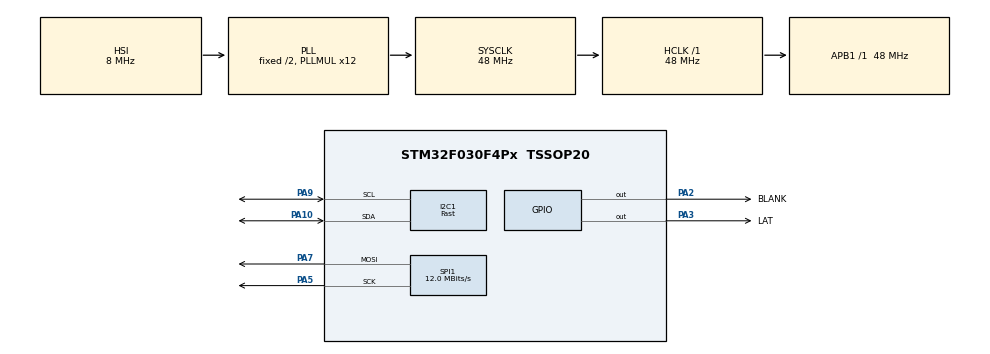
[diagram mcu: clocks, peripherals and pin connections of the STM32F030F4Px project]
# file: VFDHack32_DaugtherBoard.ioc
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Dma.I2C1_TX.0.Direction=DMA_MEMORY_TO_PERIPH
Dma.I2C1_TX.0.Instance=DMA1_Channel2
Dma.I2C1_TX.0.MemDataAlignment=DMA_MDATAALIGN_BYTE
Dma.I2C1_TX.0.MemInc=DMA_MINC_ENABLE
Dma.I2C1_TX.0.Mode=DMA_NORMAL
Dma.I2C1_TX.0.PeriphDataAlignment=DMA_PDATAALIGN_BYTE
Dma.I2C1_TX.0.PeriphInc=DMA_PINC_DISABLE
Dma.I2C1_TX.0.Priority=DMA_PRIORITY_MEDIUM
Dma.Request0=I2C1_TX
Dma.Request1=SPI1_TX
Dma.SPI1_TX.1.Direction=DMA_MEMORY_TO_PERIPH
Dma.SPI1_TX.1.Instance=DMA1_Channel3
Dma.SPI1_TX.1.MemDataAlignment=DMA_MDATAALIGN_BYTE
Dma.SPI1_TX.1.MemInc=DMA_MINC_ENABLE
Dma.SPI1_TX.1.Mode=DMA_NORMAL
Dma.SPI1_TX.1.PeriphDataAlignment=DMA_PDATAALIGN_BYTE
Dma.SPI1_TX.1.PeriphInc=DMA_PINC_DISABLE
Dma.SPI1_TX.1.Priority=DMA_PRIORITY_HIGH
I2C1.GeneralCallMode=I2C_GENERALCALL_DISABLE
I2C1.I2C_Speed_Mode=I2C_Fast
I2C1.OwnAddress=0x17
I2C1.Timing=0x0000020B
Mcu.Family=STM32F0
Mcu.Name=STM32F030F4Px
Mcu.Package=TSSOP20
NVIC.DMA1_Channel2_3_IRQn=true\:0\:0\:false\:false\:true\:false\:true
NVIC.I2C1_IRQn=true\:0\:0\:false\:false\:true\:true\:true
PA10.Mode=I2C
PA10.Signal=I2C1_SDA
PA13.Mode=Serial_Wire
PA13.Signal=SYS_SWDIO
PA14.Mode=Serial_Wire
PA14.Signal=SYS_SWCLK
PA2.GPIO_Label=BLANK
PA2.GPIO_Speed=GPIO_SPEED_FREQ_HIGH
PA2.Signal=GPIO_Output
PA3.GPIO_Label=LAT
PA3.GPIO_Speed=GPIO_SPEED_FREQ_HIGH
PA3.Signal=GPIO_Output
PA5.Mode=TX_Only_Simplex_Unidirect_Master
PA5.Signal=SPI1_SCK
PA7.Mode=TX_Only_Simplex_Unidirect_Master
PA7.Signal=SPI1_MOSI
PA9.Mode=I2C
PA9.Signal=I2C1_SCL
ProjectManager.HeapSize=0x200
ProjectManager.StackSize=0x400
ProjectManager.TargetToolchain=STM32CubeIDE
RCC.AHBFreq_Value=48000000
RCC.APB1Freq_Value=48000000
RCC.APB1TimFreq_Value=48000000
RCC.HCLKFreq_Value=48000000
RCC.PLLMUL=RCC_PLL_MUL12
RCC.SYSCLKFreq_VALUE=48000000
RCC.SYSCLKSource=RCC_SYSCLKSOURCE_PLLCLK
SPI1.BaudRatePrescaler=SPI_BAUDRATEPRESCALER_4
SPI1.CLKPolarity=SPI_POLARITY_HIGH
SPI1.CalculateBaudRate=12.0 MBits/s
SPI1.DataSize=SPI_DATASIZE_8BIT
SPI1.Direction=SPI_DIRECTION_2LINES
SPI1.FirstBit=SPI_FIRSTBIT_LSB
SPI1.Mode=SPI_MODE_MASTER
SPI1.VirtualType=VM_MASTER
board=custom

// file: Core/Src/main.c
/* USER CODE BEGIN Header */
/**
  ******************************************************************************
  * @file           : main.c
  * @brief          : Main program body
  ******************************************************************************
  * @attention
  *
  * <h2><center>&copy; Copyright (c) 2021 STMicroelectronics.
  * All rights reserved.</center></h2>
  *
  * This software component is licensed by ST under BSD 3-Clause license,
  * the "License"; You may not use this file except in compliance with the
  * License. You may obtain a copy of the License at:
  *                        opensource.org/licenses/BSD-3-Clause
  *
  ******************************************************************************
  */
/* USER CODE END Header */
#include "main.h"

/* USER CODE BEGIN Includes */
#include "MN15439A.h"
#include <stdint.h>
#include <string.h>

/* USER CODE END Includes */

/* USER CODE BEGIN PTD */
MN15439A VFDDisp;
/* USER CODE END PTD */

I2C_HandleTypeDef hi2c1;
DMA_HandleTypeDef hdma_i2c1_tx;

SPI_HandleTypeDef hspi1;
DMA_HandleTypeDef hdma_spi1_tx;

/* USER CODE BEGIN PV */
// Grid number counter
uint8_t GridNum = 1;
/* USER CODE END PV */

void SystemClock_Config(void);
static void MX_GPIO_Init(void);
static void MX_DMA_Init(void);
static void MX_SPI1_Init(void);
static void MX_I2C1_Init(void);

int main(void)
{

  /* MCU Configuration--------------------------------------------------------*/

  /* Reset of all peripherals, Initializes the Flash interface and the Systick. */
  HAL_Init();

  /* Configure the system clock */
  SystemClock_Config();

  /* Initialize all configured peripherals */
  MX_GPIO_Init();
  MX_DMA_Init();
  MX_SPI1_Init();
  MX_I2C1_Init();
  /* USER CODE BEGIN 2 */

  // VFD init
  VFDsetup(&VFDDisp, &hspi1, GPIOA, BLANK_Pin, LAT_Pin);

  /* USER CODE END 2 */

  /* Infinite loop */
  while (1)
  {

    /* USER CODE BEGIN 3 */
		VFDLoadBMP(&VFDDisp, GridNum++);
		  if(GridNum > 52)
			  GridNum = 1;
  }
  /* USER CODE END 3 */
}

void SystemClock_Config(void)
{
  RCC_OscInitTypeDef RCC_OscInitStruct = {0};
  RCC_ClkInitTypeDef RCC_ClkInitStruct = {0};
  RCC_PeriphCLKInitTypeDef PeriphClkInit = {0};

  /** Initializes the RCC Oscillators according to the specified parameters
  * in the RCC_OscInitTypeDef structure.
  */
  RCC_OscInitStruct.OscillatorType = RCC_OSCILLATORTYPE_HSI;
  RCC_OscInitStruct.HSIState = RCC_HSI_ON;
  RCC_OscInitStruct.HSICalibrationValue = RCC_HSICALIBRATION_DEFAULT;
  RCC_OscInitStruct.PLL.PLLState = RCC_PLL_ON;
  RCC_OscInitStruct.PLL.PLLSource = RCC_PLLSOURCE_HSI;
  RCC_OscInitStruct.PLL.PLLMUL = RCC_PLL_MUL12;
  RCC_OscInitStruct.PLL.PREDIV = RCC_PREDIV_DIV1;
  if (HAL_RCC_OscConfig(&RCC_OscInitStruct) != HAL_OK)
  {
    Error_Handler();
  }
  /** Initializes the CPU, AHB and APB buses clocks
  */
  RCC_ClkInitStruct.ClockType = RCC_CLOCKTYPE_HCLK|RCC_CLOCKTYPE_SYSCLK
                              |RCC_CLOCKTYPE_PCLK1;
  RCC_ClkInitStruct.SYSCLKSource = RCC_SYSCLKSOURCE_PLLCLK;
  RCC_ClkInitStruct.AHBCLKDivider = RCC_SYSCLK_DIV1;
  RCC_ClkInitStruct.APB1CLKDivider = RCC_HCLK_DIV1;

  if (HAL_RCC_ClockConfig(&RCC_ClkInitStruct, FLASH_LATENCY_1) != HAL_OK)
  {
    Error_Handler();
  }
  PeriphClkInit.PeriphClockSelection = RCC_PERIPHCLK_I2C1;
  PeriphClkInit.I2c1ClockSelection = RCC_I2C1CLKSOURCE_HSI;
  if (HAL_RCCEx_PeriphCLKConfig(&PeriphClkInit) != HAL_OK)
  {
    Error_Handler();
  }
}

static void MX_I2C1_Init(void)
{

  hi2c1.Instance = I2C1;
  hi2c1.Init.Timing = 0x0000020B;
  hi2c1.Init.OwnAddress1 = 46;
  hi2c1.Init.AddressingMode = I2C_ADDRESSINGMODE_7BIT;
  hi2c1.Init.DualAddressMode = I2C_DUALADDRESS_DISABLE;
  hi2c1.Init.OwnAddress2 = 0;
  hi2c1.Init.OwnAddress2Masks = I2C_OA2_NOMASK;
  hi2c1.Init.GeneralCallMode = I2C_GENERALCALL_DISABLE;
  hi2c1.Init.NoStretchMode = I2C_NOSTRETCH_DISABLE;
  if (HAL_I2C_Init(&hi2c1) != HAL_OK)
  {
    Error_Handler();
  }
  /** Configure Analogue filter
  */
  if (HAL_I2CEx_ConfigAnalogFilter(&hi2c1, I2C_ANALOGFILTER_ENABLE) != HAL_OK)
  {
    Error_Handler();
  }
  /** Configure Digital filter
  */
  if (HAL_I2CEx_ConfigDigitalFilter(&hi2c1, 0) != HAL_OK)
  {
    Error_Handler();
  }

}

static void MX_SPI1_Init(void)
{

  /* SPI1 parameter configuration*/
  hspi1.Instance = SPI1;
  hspi1.Init.Mode = SPI_MODE_MASTER;
  hspi1.Init.Direction = SPI_DIRECTION_2LINES;
  hspi1.Init.DataSize = SPI_DATASIZE_8BIT;
  hspi1.Init.CLKPolarity = SPI_POLARITY_HIGH;
  hspi1.Init.CLKPhase = SPI_PHASE_1EDGE;
  hspi1.Init.NSS = SPI_NSS_SOFT;
  hspi1.Init.BaudRatePrescaler = SPI_BAUDRATEPRESCALER_4;
  hspi1.Init.FirstBit = SPI_FIRSTBIT_LSB;
  hspi1.Init.TIMode = SPI_TIMODE_DISABLE;
  hspi1.Init.CRCCalculation = SPI_CRCCALCULATION_DISABLE;
  hspi1.Init.CRCPolynomial = 7;
  hspi1.Init.CRCLength = SPI_CRC_LENGTH_DATASIZE;
  hspi1.Init.NSSPMode = SPI_NSS_PULSE_ENABLE;
  if (HAL_SPI_Init(&hspi1) != HAL_OK)
  {
    Error_Handler();
  }

}

static void MX_DMA_Init(void)
{

  /* DMA controller clock enable */
  __HAL_RCC_DMA1_CLK_ENABLE();

  /* DMA interrupt init */
  /* DMA1_Channel2_3_IRQn interrupt configuration */
  HAL_NVIC_SetPriority(DMA1_Channel2_3_IRQn, 0, 0);
  HAL_NVIC_EnableIRQ(DMA1_Channel2_3_IRQn);

}

static void MX_GPIO_Init(void)
{
  GPIO_InitTypeDef GPIO_InitStruct = {0};

  /* GPIO Ports Clock Enable */
  __HAL_RCC_GPIOA_CLK_ENABLE();

  /*Configure GPIO pin Output Level */
  HAL_GPIO_WritePin(GPIOA, BLANK_Pin|LAT_Pin, GPIO_PIN_RESET);

  /*Configure GPIO pins : BLANK_Pin LAT_Pin */
  GPIO_InitStruct.Pin = BLANK_Pin|LAT_Pin;
  GPIO_InitStruct.Mode = GPIO_MODE_OUTPUT_PP;
  GPIO_InitStruct.Pull = GPIO_NOPULL;
  GPIO_InitStruct.Speed = GPIO_SPEED_FREQ_HIGH;
  HAL_GPIO_Init(GPIOA, &GPIO_InitStruct);

}

/* USER CODE BEGIN 4 */
// Handle incoming I2C request
void HAL_I2C_AddrCallback(I2C_HandleTypeDef *hi2c, uint8_t TransferDirection, uint16_t AddrMatchCode){
	// DOnt need to check the i2c instance since there's only 1 i2c (I2C1).
		if(AddrMatchCode == hi2c->Init.OwnAddress1){// If address match
			HAL_I2C_Slave_Transmit_DMA(hi2c, FB0, 780);
		}

}
/* USER CODE END 4 */

void Error_Handler(void)
{
  __disable_irq();
  while (1)
  {
  }
}

/************************ (C) COPYRIGHT STMicroelectronics *****END OF FILE****/
